# CC13x0 register map
File version: 2.0
CPU: CM3 r2p1, little endian, no MPU, no FPU, 0x3 interrupt priority bits, 0x0 interrupts
Registers are 32-bit, read-write, reset 0x0 unless marked. A register's access mark holds for its fields unless they carry their own. Offsets are from the block's base; [hi:lo] are bit positions; {n}, {i} and the like mark numbered series.

## GPIO — MCU GPIO - I/F for controlling and reading IO status and IO event status
Base 0x40022000
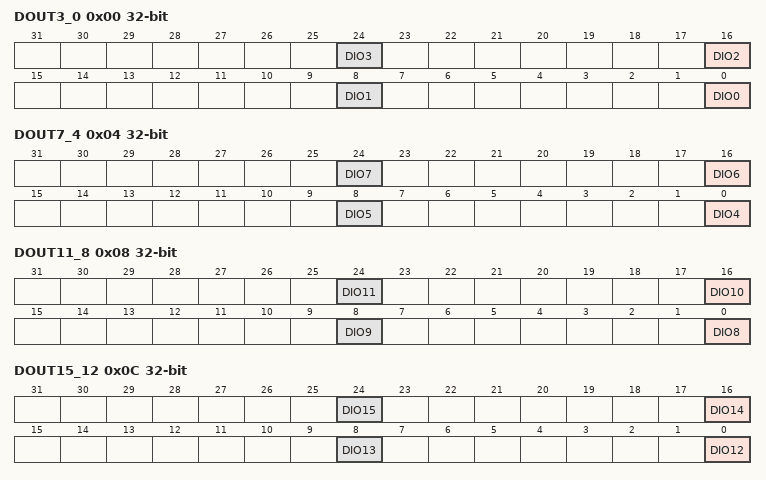
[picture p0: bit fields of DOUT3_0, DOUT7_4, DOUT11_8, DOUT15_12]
0x00 DOUT3_0 — Data Out 0 to 3 Alias register for byte access to each bit in DOUT31_0
  [8n] DIO{n} (n=0..3)
0x04 DOUT7_4 — Data Out 4 to 7 Alias register for byte access to each bit in DOUT31_0
  [8n-32] DIO{n} (n=4..7)
0x08 DOUT11_8 — Data Out 8 to 11 Alias register for byte access to each bit in DOUT31_0
  [8n-64] DIO{n} (n=8..11)
0x0C DOUT15_12 — Data Out 12 to 15 Alias register for byte access to each bit in DOUT31_0
  [8n-96] DIO{n} (n=12..15)
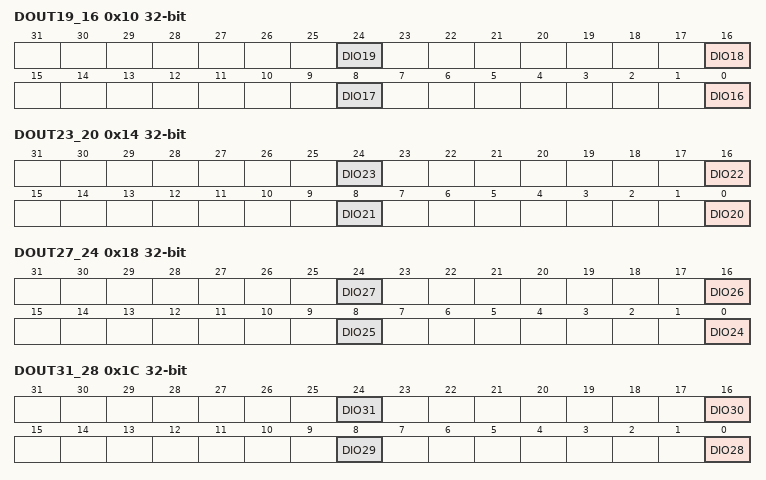
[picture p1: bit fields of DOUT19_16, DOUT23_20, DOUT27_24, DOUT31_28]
0x10 DOUT19_16 — Data Out 16 to 19 Alias register for byte access to each bit in DOUT31_0
  [8n-128] DIO{n} (n=16..19)
0x14 DOUT23_20 — Data Out 20 to 23 Alias register for byte access to each bit in DOUT31_0
  [8n-160] DIO{n} (n=20..23)
0x18 DOUT27_24 — Data Out 24 to 27 Alias register for byte access to each bit in DOUT31_0
  [8n-192] DIO{n} (n=24..27)
0x1C DOUT31_28 — Data Out 28 to 31 Alias register for byte access to each bit in DOUT31_0
  [8n-224] DIO{n} (n=28..31)
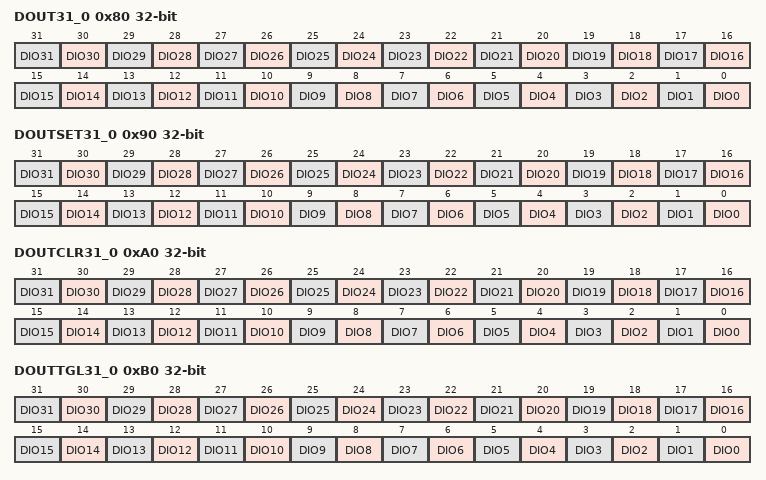
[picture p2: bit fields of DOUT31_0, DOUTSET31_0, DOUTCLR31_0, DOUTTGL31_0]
0x80 DOUT31_0 — Data Output for DIO 0 to 31
  [n] DIO{n} (n=0..31)
0x90 DOUTSET31_0 wo — Data Out Set Writing 1 to a bit position sets the corresponding bit in the DOUT31_0 register
  [n] DIO{n} write-1-sets (n=0..31)
0xA0 DOUTCLR31_0 wo — Data Out Clear Writing 1 to a bit position clears the corresponding bit in the DOUT31_0 register
  [n] DIO{n} write-1-clears (n=0..31)
0xB0 DOUTTGL31_0 — Data Out Toggle Writing 1 to a bit position will invert the corresponding DIO output.
  [n] DIO{n} (n=0..31)
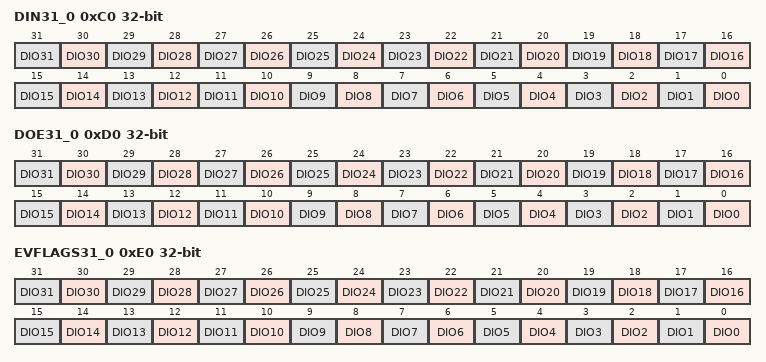
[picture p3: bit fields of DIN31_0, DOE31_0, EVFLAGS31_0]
0xC0 DIN31_0 ro — Data Input from DIO 0 to 31
  [n] DIO{n} (n=0..31)
0xD0 DOE31_0 — Data Output Enable for DIO 0 to 31
  [n] DIO{n} (n=0..31)
0xE0 EVFLAGS31_0 — Event Register for DIO 0 to 31 Reading this registers will return 1 for triggered event and 0 for non-triggered events. Writing a 1 to a bit field will clear the event. The configuration of events is done inside MCU IOC, e.g. events for DIO #0 is configured in IOC:IOCFG0.EDGE_DET and IOC:IOCFG0.EDGE_IRQ_EN.
  [n] DIO{n} write-1-clears (n=0..31)

## I2C0 — I2CMaster/Slave Serial Controler
Base 0x40002000
0x00 SOAR — Slave Own Address This register consists of seven address bits that identify this I2C device on the I2C bus.
  [6:0] OAR
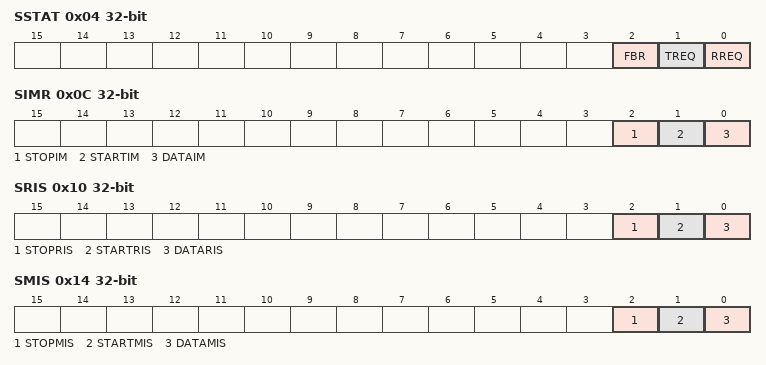
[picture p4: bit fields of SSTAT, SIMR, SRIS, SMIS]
0x04 SSTAT ro — Slave Status Note: This register shares address with SCTL, meaning that this register functions as a control register when written, and a status register when read.
  [2] FBR, [1] TREQ, [0] RREQ
0x04 SCTL wo — Slave Control Note: This register shares address with SSTAT, meaning that this register functions as a control register when written, and a status register when read.
  [0] DA
0x08 SDR — Slave Data This register contains the data to be transmitted when in the Slave Transmit state, and the data received when in the Slave Receive state.
  [7:0] DATA
0x0C SIMR — Slave Interrupt Mask This register controls whether a raw interrupt is promoted to a controller interrupt.
  [2] STOPIM, [1] STARTIM, [0] DATAIM
0x10 SRIS ro — Slave Raw Interrupt Status This register shows the unmasked interrupt status.
  [2] STOPRIS, [1] STARTRIS, [0] DATARIS
0x14 SMIS ro — Slave Masked Interrupt Status This register show which interrupt is active (based on result from SRIS and SIMR).
  [2] STOPMIS, [1] STARTMIS, [0] DATAMIS
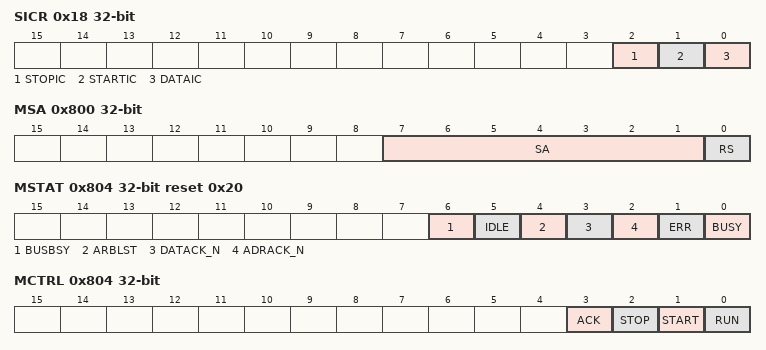
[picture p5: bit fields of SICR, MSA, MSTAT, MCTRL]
0x18 SICR wo — Slave Interrupt Clear This register clears the raw interrupt SRIS.
  [2] STOPIC, [1] STARTIC, [0] DATAIC
0x800 MSA — Master Salve Address This register contains seven address bits of the slave to be accessed by the master (a6-a0), and an RS bit determining if the next operation is a receive or transmit.
  [7:1] SA, [0] RS
0x804 MSTAT ro reset 0x20 — Master Status
  [6] BUSBSY, [5] IDLE, [4] ARBLST, [3] DATACK_N, [2] ADRACK_N, [1] ERR, [0] BUSY
0x804 MCTRL wo — Master Control This register accesses status bits when read and control bits when written. When read, the status register indicates the state of the I2C bus controller as stated in MSTAT. When written, the control register configures the I2C controller operation. To generate a single transmit cycle, the I2C Master Slave Address (MSA) register is written with the desired address, the MSA.RS bit is cleared, and this register is written with * ACK=X (0 or 1), * STOP=1, * START=1, * RUN=1 to perform the operation and stop. When the operation is completed (or aborted due an error), an interrupt becomes active and the data may be read from the MDR register.
  [3] ACK, [2] STOP, [1] START, [0] RUN
0x808 MDR — Master Data This register contains the data to be transmitted when in the Master Transmit state and the data received when in the Master Receive state.
  [7:0] DATA
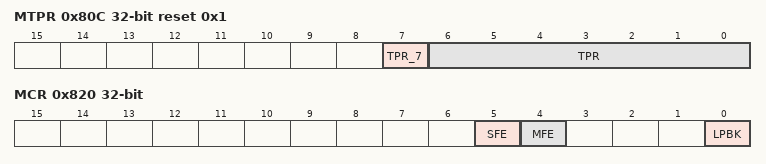
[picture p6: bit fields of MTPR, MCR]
0x80C MTPR reset 0x1 — I2C Master Timer Period This register specifies the period of the SCL clock.
  [7] TPR_7, [6:0] TPR
0x810 MIMR — Master Interrupt Mask This register controls whether a raw interrupt is promoted to a controller interrupt.
  [0] IM
0x814 MRIS ro — Master Raw Interrupt Status This register show the unmasked interrupt status.
  [0] RIS
0x818 MMIS ro — Master Masked Interrupt Status This register show which interrupt is active (based on result from MRIS and MIMR).
  [0] MIS
0x81C MICR wo — Master Interrupt Clear This register clears the raw and masked interrupt.
  [0] IC
0x820 MCR — Master Configuration This register configures the mode (Master or Slave) and sets the interface for test mode loopback.
  [5] SFE, [4] MFE, [0] LPBK
